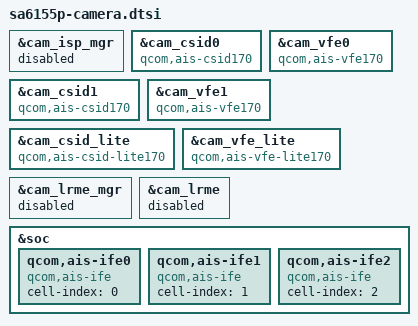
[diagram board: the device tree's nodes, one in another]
/*
 * Copyright (c) 2020, The Linux Foundation. All rights reserved.
 *
 * This program is free software; you can redistribute it and/or modify
 * it under the terms of the GNU General Public License version 2 and
 * only version 2 as published by the Free Software Foundation.
 *
 * This program is distributed in the hope that it will be useful,
 * but WITHOUT ANY WARRANTY; without even the implied warranty of
 * MERCHANTABILITY or FITNESS FOR A PARTICULAR PURPOSE.  See the
 * GNU General Public License for more details.
 */

&cam_isp_mgr {
	status = "disabled";
};

&cam_csid0 {
	compatible = "qcom,ais-csid170";
};

&cam_vfe0 {
	compatible = "qcom,ais-vfe170";
};

&cam_csid1 {
	compatible = "qcom,ais-csid170";
};

&cam_vfe1 {
	compatible = "qcom,ais-vfe170";
};

&cam_csid_lite {
	compatible = "qcom,ais-csid-lite170";
};

&cam_vfe_lite {
	compatible = "qcom,ais-vfe-lite170";
};

&cam_lrme_mgr {
	status = "disabled";
};
&cam_lrme {
	status = "disabled";
};


&soc {
	/delete-node/ cam_isp_mgr;
	/delete-node/ cam_fd_mgr;
	/delete-node/ cam_fd;
	/delete-node/ cam_lrme_mgr;
	/delete-node/ cam_lrme;

	qcom,ais-ife0 {
		compatible = "qcom,ais-ife";
		cell-index = <0>;
		status = "ok";
	};

	qcom,ais-ife1 {
		compatible = "qcom,ais-ife";
		cell-index = <1>;
		status = "ok";
	};

	qcom,ais-ife2 {
		compatible = "qcom,ais-ife";
		cell-index = <2>;
		status = "ok";
	};
};
